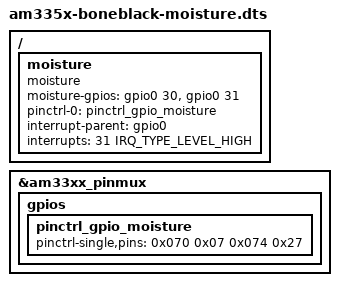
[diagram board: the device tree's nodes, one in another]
/*
 Moisture sensor DTS
 */
 
#include <dt-bindings/interrupt-controller/irq.h>
#include "am335x-boneblack.dts"


// have a look at:
// Documentation/gpio/board.txt

/ {
   
  moisture {
    compatible = "moisture";
    moisture-gpios = <&gpio0 30 GPIO_ACTIVE_HIGH>, // P9_11
                     <&gpio0 31 GPIO_ACTIVE_HIGH>; // P9_13
    pinctrl-0 = <&pinctrl_gpio_moisture>;
    pinctrl-names = "default";
    status = "okay";
    
    interrupt-parent = <&gpio0>;
    interrupts = <31 IRQ_TYPE_LEVEL_HIGH>;
  };
  
};

&am33xx_pinmux {
  
  gpios {  
    pinctrl_gpio_moisture: pinctrl_gpio_moisture {
      pinctrl-single,pins = <
        0x070 0x07 // AM33XX_IOPAD(0x070, PIN_OUTPUT_PULLDOWN | MUX_MODE7)
        0x074 0x27 // AM33XX_IOPAD(0x074, PIN_INPUT_PULLDOWN | MUX_MODE7)
      >;
    };
  };
  
};


